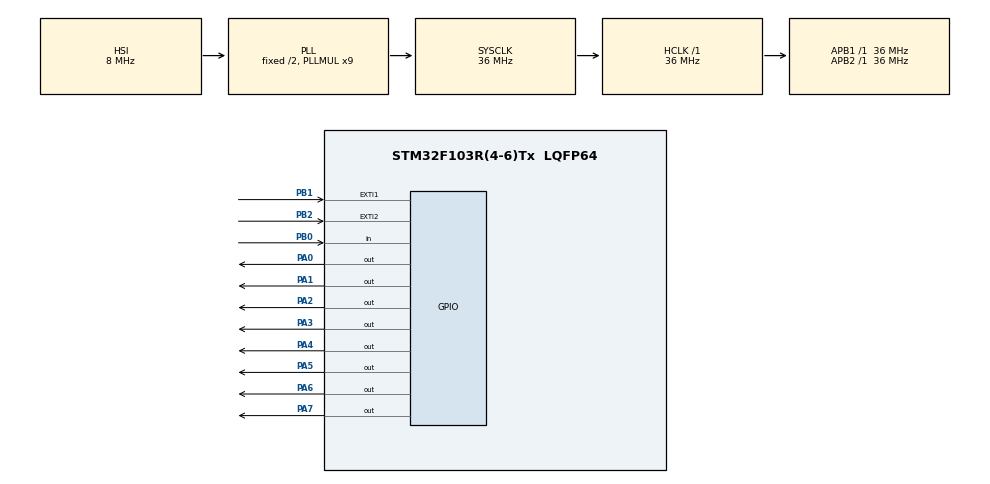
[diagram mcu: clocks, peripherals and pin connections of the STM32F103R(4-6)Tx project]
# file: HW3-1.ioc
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Mcu.Family=STM32F1
Mcu.Name=STM32F103R(4-6)Tx
Mcu.Package=LQFP64
NVIC.EXTI1_IRQn=true\:0\:0\:false\:false\:true\:true\:true\:true
NVIC.EXTI2_IRQn=true\:0\:0\:false\:false\:true\:true\:true\:true
NVIC.PriorityGroup=NVIC_PRIORITYGROUP_4
PA0-WKUP.Signal=GPIO_Output
PA1.Signal=GPIO_Output
PA2.Signal=GPIO_Output
PA3.Signal=GPIO_Output
PA4.Signal=GPIO_Output
PA5.Signal=GPIO_Output
PA6.Signal=GPIO_Output
PA7.Signal=GPIO_Output
PB0.GPIO_PuPd=GPIO_PULLDOWN
PB0.Signal=GPIO_Input
PB1.GPIO_PuPd=GPIO_PULLDOWN
PB1.Signal=GPXTI1
PB2.GPIO_PuPd=GPIO_PULLDOWN
PB2.Signal=GPXTI2
ProjectManager.HeapSize=0x200
ProjectManager.StackSize=0x400
ProjectManager.TargetToolchain=STM32CubeIDE
RCC.AHBFreq_Value=36000000
RCC.APB1Freq_Value=36000000
RCC.APB1TimFreq_Value=36000000
RCC.APB2Freq_Value=36000000
RCC.APB2TimFreq_Value=36000000
RCC.HCLKFreq_Value=36000000
RCC.PLLMUL=RCC_PLL_MUL9
RCC.SYSCLKFreq_VALUE=36000000
RCC.SYSCLKSource=RCC_SYSCLKSOURCE_PLLCLK
RCC.USBFreq_Value=36000000
board=custom

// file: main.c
/* USER CODE BEGIN Header */
/**
  ******************************************************************************
  * @file           : main.c
  * @brief          : Main program body
  ******************************************************************************
  * @attention
  *
  * Copyright (c) 2026 STMicroelectronics.
  * All rights reserved.
  *
  * This software is licensed under terms that can be found in the LICENSE file
  * in the root directory of this software component.
  * If no LICENSE file comes with this software, it is provided AS-IS.
  *
  ******************************************************************************
  */
/* USER CODE END Header */
#include "main.h"

/* USER CODE BEGIN PV */
uint8_t segCode[10] = {0x3F, 0x06, 0x5B, 0x4F, 0x66, 0x6D, 0x7D, 0x07, 0x7F, 0x6F};
volatile uint8_t systemState = 0;
/* USER CODE END PV */

void SystemClock_Config(void);
static void MX_GPIO_Init(void);

int main(void)
{

  /* MCU Configuration--------------------------------------------------------*/

  /* Reset of all peripherals, Initializes the Flash interface and the Systick. */
  HAL_Init();

  /* Configure the system clock */
  SystemClock_Config();

  /* Initialize all configured peripherals */
  MX_GPIO_Init();
  /* USER CODE BEGIN 2 */
  uint8_t currentNumber = 0;
  HAL_GPIO_WritePin(GPIOA, GPIO_PIN_0 | GPIO_PIN_1 | GPIO_PIN_2 | GPIO_PIN_3 | GPIO_PIN_4 | GPIO_PIN_5, GPIO_PIN_SET);
  HAL_GPIO_WritePin(GPIOA, GPIO_PIN_6, GPIO_PIN_RESET);
  /* USER CODE END 2 */

  /* Infinite loop */
  while (1)
  {
	  if (systemState == 0) {
	      GPIOA->ODR = (GPIOA->ODR & 0xFF80) | segCode[0];
	      if (HAL_GPIO_ReadPin(GPIOB, GPIO_PIN_0) == GPIO_PIN_SET) {
	          systemState = 1;
	          currentNumber = 0;
	      }
	  } else if (systemState == 1) {
	      GPIOA->ODR = (GPIOA->ODR & 0xFF80) | segCode[currentNumber];
	      HAL_Delay(1000);
	      if (systemState == 1) {
	          currentNumber++;
	          if (currentNumber > 9) {
	              currentNumber = 0;
	          }
	      }
	  } else if (systemState == 2) {
	      GPIOA->ODR = (GPIOA->ODR & 0xFF80) | segCode[1];
	  } else if (systemState == 3) {
	      GPIOA->ODR = (GPIOA->ODR & 0xFF80) | segCode[9];
	  }
  }
}

void SystemClock_Config(void)
{
  RCC_OscInitTypeDef RCC_OscInitStruct = {0};
  RCC_ClkInitTypeDef RCC_ClkInitStruct = {0};

  /** Initializes the RCC Oscillators according to the specified parameters
  * in the RCC_OscInitTypeDef structure.
  */
  RCC_OscInitStruct.OscillatorType = RCC_OSCILLATORTYPE_HSI;
  RCC_OscInitStruct.HSIState = RCC_HSI_ON;
  RCC_OscInitStruct.HSICalibrationValue = RCC_HSICALIBRATION_DEFAULT;
  RCC_OscInitStruct.PLL.PLLState = RCC_PLL_ON;
  RCC_OscInitStruct.PLL.PLLSource = RCC_PLLSOURCE_HSI_DIV2;
  RCC_OscInitStruct.PLL.PLLMUL = RCC_PLL_MUL9;
  if (HAL_RCC_OscConfig(&RCC_OscInitStruct) != HAL_OK)
  {
    Error_Handler();
  }

  /** Initializes the CPU, AHB and APB buses clocks
  */
  RCC_ClkInitStruct.ClockType = RCC_CLOCKTYPE_HCLK|RCC_CLOCKTYPE_SYSCLK
                              |RCC_CLOCKTYPE_PCLK1|RCC_CLOCKTYPE_PCLK2;
  RCC_ClkInitStruct.SYSCLKSource = RCC_SYSCLKSOURCE_PLLCLK;
  RCC_ClkInitStruct.AHBCLKDivider = RCC_SYSCLK_DIV1;
  RCC_ClkInitStruct.APB1CLKDivider = RCC_HCLK_DIV1;
  RCC_ClkInitStruct.APB2CLKDivider = RCC_HCLK_DIV1;

  if (HAL_RCC_ClockConfig(&RCC_ClkInitStruct, FLASH_LATENCY_1) != HAL_OK)
  {
    Error_Handler();
  }
}

static void MX_GPIO_Init(void)
{
  GPIO_InitTypeDef GPIO_InitStruct = {0};

  /* GPIO Ports Clock Enable */
  __HAL_RCC_GPIOA_CLK_ENABLE();
  __HAL_RCC_GPIOB_CLK_ENABLE();

  /*Configure GPIO pin Output Level */
  HAL_GPIO_WritePin(GPIOA, GPIO_PIN_0|GPIO_PIN_1|GPIO_PIN_2|GPIO_PIN_3
                          |GPIO_PIN_4|GPIO_PIN_5|GPIO_PIN_6|GPIO_PIN_7, GPIO_PIN_RESET);

  /*Configure GPIO pins : PA0 PA1 PA2 PA3
                           PA4 PA5 PA6 PA7 */
  GPIO_InitStruct.Pin = GPIO_PIN_0|GPIO_PIN_1|GPIO_PIN_2|GPIO_PIN_3
                          |GPIO_PIN_4|GPIO_PIN_5|GPIO_PIN_6|GPIO_PIN_7;
  GPIO_InitStruct.Mode = GPIO_MODE_OUTPUT_PP;
  GPIO_InitStruct.Pull = GPIO_NOPULL;
  GPIO_InitStruct.Speed = GPIO_SPEED_FREQ_LOW;
  HAL_GPIO_Init(GPIOA, &GPIO_InitStruct);

  /*Configure GPIO pin : PB0 */
  GPIO_InitStruct.Pin = GPIO_PIN_0;
  GPIO_InitStruct.Mode = GPIO_MODE_INPUT;
  GPIO_InitStruct.Pull = GPIO_PULLDOWN;
  HAL_GPIO_Init(GPIOB, &GPIO_InitStruct);

  /*Configure GPIO pins : PB1 PB2 */
  GPIO_InitStruct.Pin = GPIO_PIN_1|GPIO_PIN_2;
  GPIO_InitStruct.Mode = GPIO_MODE_IT_RISING;
  GPIO_InitStruct.Pull = GPIO_PULLDOWN;
  HAL_GPIO_Init(GPIOB, &GPIO_InitStruct);

  /* EXTI interrupt init*/
  HAL_NVIC_SetPriority(EXTI1_IRQn, 0, 0);
  HAL_NVIC_EnableIRQ(EXTI1_IRQn);

  HAL_NVIC_SetPriority(EXTI2_IRQn, 0, 0);
  HAL_NVIC_EnableIRQ(EXTI2_IRQn);

}

/* USER CODE BEGIN 4 */
void HAL_GPIO_EXTI_Callback(uint16_t GPIO_Pin) {
    if (GPIO_Pin == GPIO_PIN_1) {
        systemState = 2;
    } else if (GPIO_Pin == GPIO_PIN_2) {
        systemState = 3;
    }
}
/* USER CODE END 4 */

void Error_Handler(void)
{
  __disable_irq();
  while (1)
  {
  }
}
